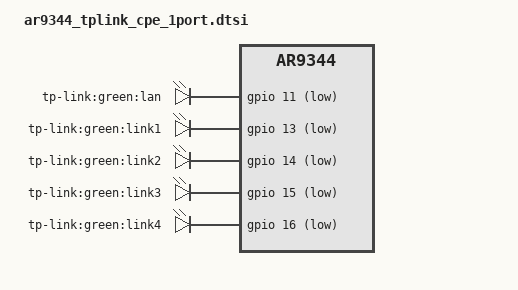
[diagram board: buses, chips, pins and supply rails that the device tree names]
// SPDX-License-Identifier: GPL-2.0-or-later OR MIT

#include "ar9344_tplink_cpe.dtsi"

/ {
	aliases {
		led-boot = &led_system;
		led-failsafe = &led_system;
		led-running = &led_system;
		led-upgrade = &led_system;
	};

	leds {
		compatible = "gpio-leds";

		lan {
			label = "tp-link:green:lan";
			gpios = <&gpio 11 GPIO_ACTIVE_LOW>;
		};

		link1 {
			label = "tp-link:green:link1";
			gpios = <&gpio 13 GPIO_ACTIVE_LOW>;
		};

		link2 {
			label = "tp-link:green:link2";
			gpios = <&gpio 14 GPIO_ACTIVE_LOW>;
		};

		link3 {
			label = "tp-link:green:link3";
			gpios = <&gpio 15 GPIO_ACTIVE_LOW>;
		};

		led_system: link4 {
			label = "tp-link:green:link4";
			gpios = <&gpio 16 GPIO_ACTIVE_LOW>;
		};
	};
};

&eth1 {
	compatible = "syscon", "simple-mfd";
};
